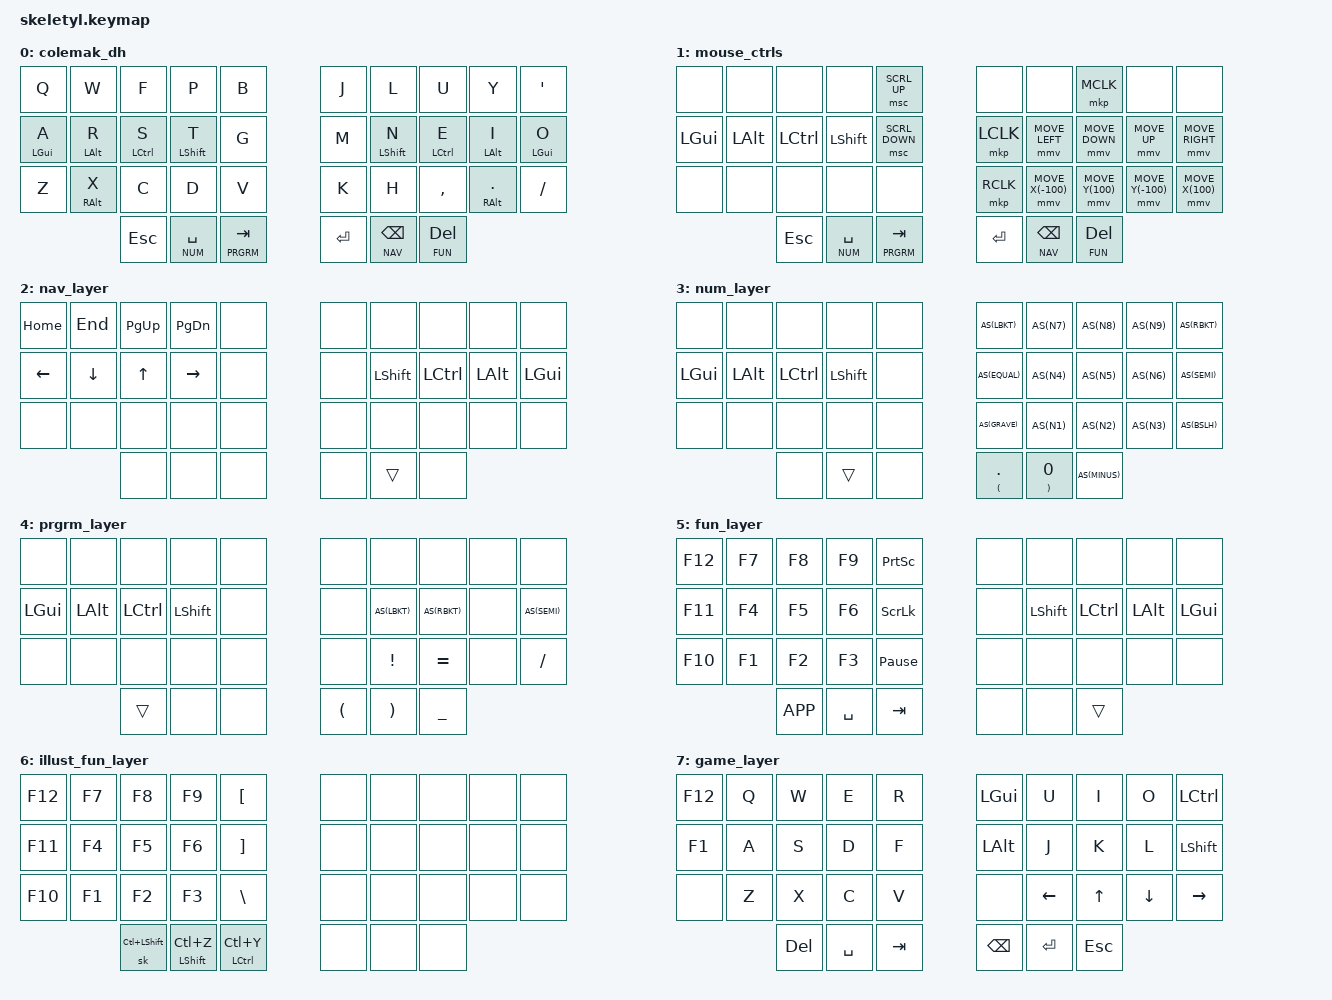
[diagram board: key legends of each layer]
#include <behaviors.dtsi>
#include <dt-bindings/zmk/keys.h>
#include <dt-bindings/zmk/bt.h>
#include <dt-bindings/zmk/outputs.h>

#define ZMK_POINTING_DEFAULT_MOVE_VAL 1500  // default: 600
#define ZMK_POINTING_DEFAULT_SCRL_VAL 20    // default: 10
#include <dt-bindings/zmk/pointing.h>

// Modified keymap based on personal experience, with some improvements based on Miryoku layout.

#define COLDH  0
#define MOUSE   1
#define NAV     2
#define NUM     3
#define PRGRM   4
#define FUN     5
#define ILLUST  6
#define GAME    7

#define AS(keycode) &as LS(keycode) keycode     // Autoshift Macro

/ {
    behaviors {
        as: auto_shift {
            compatible = "zmk,behavior-hold-tap";
            label = "AUTO_SHIFT";
            #binding-cells = <2>;
            tapping-term-ms = <500>;
            quick-tap-ms = <0>;
            flavor = "tap-preferred";
            bindings = <&kp>, <&kp>;
        };
        hm: homerow_mods {
            compatible = "zmk,behavior-hold-tap";
            label = "HOMEROW_MODS";
            #binding-cells = <2>;
            tapping-term-ms = <1000>;
            quick-tap-ms = <0>;
            flavor = "tap-preferred";
            bindings = <&kp>, <&kp>;
        };
        hmp: homerow_mods_pinky {
            compatible = "zmk,behavior-hold-tap";
            label = "HOMEROW_MODS";
            #binding-cells = <2>;
            tapping-term-ms = <200>;
            quick-tap-ms = <0>;
            flavor = "tap-preferred";
            bindings = <&kp>, <&kp>;
        };
    };

    combos {
        compatible = "zmk,combos";

        // Combos for media player.
        // I often switch songs while drawing, so I assign the
        // combos on left hand side.

        combo_med_next {
            timeout-ms = <50>;
            key-positions = <2 3>;
            bindings = <&kp C_NEXT>;
        };
        combo_med_prev {
            timeout-ms = <50>;
            key-positions = <1 2>;
            bindings = <&kp C_PREV>;
        };
        combo_med_pp {
            timeout-ms = <50>;
            key-positions = <1 4>;
            bindings = <&kp C_PP>;
        };
        combo_med_stop {
            timeout-ms = <50>;
            key-positions = <1 3>;
            bindings = <&kp C_STOP>;
        };
        combo_med_vol_up {
            timeout-ms = <50>;
            key-positions = <2 13>;
            bindings = <&kp C_VOL_UP>;
        };
        combo_med_vol_dn {
            timeout-ms = <50>;
            key-positions = <3 12>;
            bindings = <&kp C_VOL_DN>;
        };
        combo_med_mute {
            timeout-ms = <50>;
            key-positions = <12 14>;
            bindings = <&kp C_MUTE>;
        };

        // combo for toggling illust layer
        combo_tg_illust {
            timeout-ms = <50>;
            key-positions = <21 22 23>;
            bindings = <&tog ILLUST>;
        };

        // Combo for toggling the Mouse layout
        combo_tg_mouse {
            timeout-ms = <50>;
            key-positions = <6 7 8>;
            bindings = <&tog MOUSE>;
        };

        // Combo for toggling minimal game layout
        combo_tg_game {
            timeout-ms = <50>;
            key-positions = <7 8>;
            bindings = <&tog GAME>;
        };

        // Combo for bluetooth control
        // (i.e. switch among the devices).
        combo_bt_next {
            timeout-ms = <50>;
            key-positions = <27 28>;
            bindings = <&bt BT_NXT>;
        };
        combo_bt_prev {
            timeout-ms = <50>;
            key-positions = <26 27>;
            bindings = <&bt BT_PRV>;
        };
        combo_bt_clr_all {
            timeout-ms = <50>;
            key-positions = <0 9>;
            bindings = <&bt BT_CLR_ALL>;
        };
        combo_bt_out_tog {
            timeout-ms = <50>;
            key-positions = <4 5>;
            bindings = <&out OUT_TOG>;
        };

    };

    keymap {
        compatible = "zmk,keymap";

        colemak_dh {
            bindings = <
    &kp Q       &kp W       &kp F       &kp P           &kp B           &kp J       &kp L       &kp U       &kp Y           &kp SQT
    &hmp LGUI A &hm LALT R  &hm LCTRL S &hm LSHFT T     &kp G           &kp M       &hm LSHFT N &hm LCTRL E &hm LALT I      &hmp LGUI O
    &kp Z       &hm RALT X  &kp C       &kp D           &kp V           &kp K       &kp H       &kp COMMA   &hm RALT DOT    &kp FSLH
                            &kp ESC     &lt NUM SPACE   &lt PRGRM TAB     &kp RET    &lt NAV BSPC &lt FUN DEL
            >;
        };

        mouse_ctrls {
            bindings = <
    &none       &none       &none       &none           &msc SCRL_UP          &none      &none               &mkp MCLK            &none                  &none
    &kp LGUI    &kp LALT    &kp LCTRL   &kp LSHFT       &msc SCRL_DOWN        &mkp LCLK  &mmv MOVE_LEFT      &mmv MOVE_DOWN       &mmv MOVE_UP           &mmv MOVE_RIGHT
    &none       &none       &none       &none           &none                &mkp RCLK   &mmv MOVE_X(-100)   &mmv MOVE_Y(100)    &mmv MOVE_Y(-100)       &mmv MOVE_X(100)
                            &kp ESC     &lt NUM SPACE   &lt PRGRM TAB        &kp RET     &lt NAV BSPC        &lt FUN DEL
            >;
        };

        nav_layer {
            bindings = <
    &kp HOME    &kp END         &kp PG_UP      &kp PG_DN       &none           &none       &none         &none       &none           &none
    &kp LEFT    &kp DOWN        &kp UP         &kp RIGHT       &none           &none       &kp LSHFT     &kp LCTRL   &kp LALT        &kp LGUI
    &none       &none           &none          &none           &none           &none       &none         &none       &none           &none
                                &none          &none           &none           &none       &trans        &none
            >;
        };

        num_layer {
            bindings = <
    &none       &none       &none       &none       &none       AS(LBKT)        AS(N7)      AS(N8)      AS(N9)  AS(RBKT)
    &kp LGUI    &kp LALT    &kp LCTRL   &kp LSHFT   &none       AS(EQUAL)       AS(N4)      AS(N5)      AS(N6)  AS(SEMI)
    &none       &none       &none       &none       &none       AS(GRAVE)       AS(N1)      AS(N2)      AS(N3)  AS(BSLH)
                            &none       &trans      &none       &as LPAR DOT    &as RPAR N0 AS(MINUS)
            >;
        };

       prgrm_layer {
           bindings = <
    &none       &none       &none       &none       &none       &none       &none       &none       &none   &none
    &kp LGUI    &kp LALT    &kp LCTRL   &kp LSHFT   &none       &none       AS(LBKT)    AS(RBKT)    &none   AS(SEMI)
    &none       &none       &none       &none       &none       &none       &kp EXCL    &kp EQUAL   &none   &kp FSLH
                            &trans      &none       &none       &kp LPAR    &kp RPAR    &kp UNDER
            >;
        };

        fun_layer {
            bindings = <
    &kp F12 &kp F7  &kp F8      &kp F9      &kp PSCRN       &none   &none       &none       &none       &none
    &kp F11 &kp F4  &kp F5      &kp F6      &kp SLCK        &none   &kp LSHFT   &kp LCTRL   &kp LALT    &kp LGUI
    &kp F10 &kp F1  &kp F2      &kp F3      &kp PAUSE_BREAK &none   &none       &none       &none       &none
                    &kp K_APP   &kp SPACE   &kp TAB         &none   &none       &trans
            >;
        };

        illust_fun_layer {
            bindings = <
    &kp F12 &kp F7  &kp F8          &kp F9          &kp LBKT        &none   &none   &none   &none   &none
    &kp F11 &kp F4  &kp F5          &kp F6          &kp RBKT        &none   &none   &none   &none   &none
    &kp F10 &kp F1  &kp F2          &kp F3          &kp BSLH        &none   &none   &none   &none   &none
                    &sk LC(LSHFT)   &mt LSHFT LC(Z) &mt LCTRL LC(Y) &none   &none   &none
            >;
        };

        game_layer {
            bindings = <
    &kp F12 &kp Q  &kp W  &kp E  &kp R              &kp LGUI   &kp U   &kp I   &kp O   &kp LCTRL
    &kp F1 &kp A  &kp S  &kp D  &kp F              &kp LALT   &kp J   &kp K   &kp L   &kp LSHFT
    &none &kp Z  &kp X  &kp C  &kp V                 &none   &kp LEFT   &kp UP   &kp DOWN   &kp RIGHT
                    &kp DEL &kp SPACE &kp TAB   &kp BSPC   &kp RET   &kp ESC
            >;
        };

    };
};
